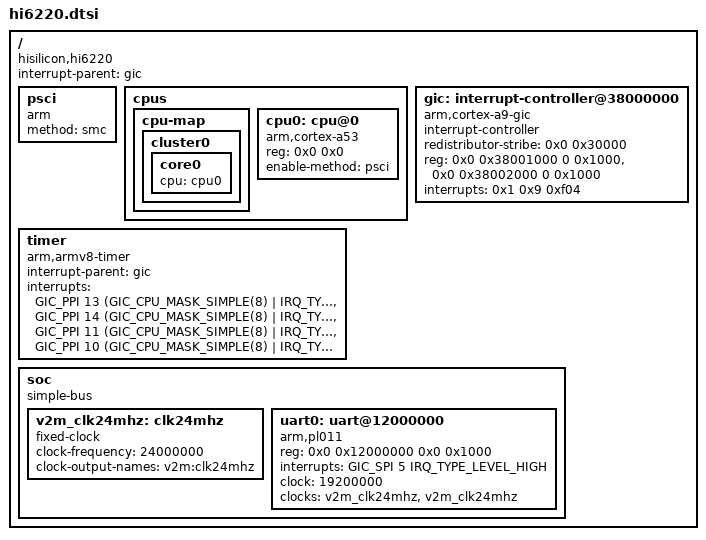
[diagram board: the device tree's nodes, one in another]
/*
 * dts file for Hisilicon Hi6220 SoC
 *
 * Copyright (C) 2015, Hisilicon Ltd.
 */

#include <dt-bindings/interrupt-controller/arm-gic.h>
#include <dt-bindings/clock/hi6220-clock.h>

/ {
	compatible = "hisilicon,hi6220";
	interrupt-parent = <&gic>;
	#address-cells = <2>;
	#size-cells = <2>;

	psci {
		compatible = "arm";
		method = "smc";
	};

	cpus {
		#address-cells = <2>;
		#size-cells = <0>;

		cpu-map {
			cluster0 {
				core0 {
					cpu = <&cpu0>;
				};
			};
		};

		cpu0: cpu@0 {
			compatible = "arm,cortex-a53", "arm,armv8";
			device_type = "cpu";
			reg = <0x0 0x0>;
			enable-method = "psci";
		};


	};

	gic: interrupt-controller@38000000 {
		compatible = "arm,cortex-a9-gic";
		#interrupt-cells = <0x3>;
		#address-cells = <0x2>;
		#size-cells = <0x2>;
		interrupt-controller;
		redistributor-stribe = <0x0 0x30000>;
		reg = <0x0 0x38001000 0 0x1000>, /* GICD */
		      <0x0 0x38002000 0 0x1000>; /* GICC */
		interrupts = <0x1 0x9 0xf04>;
		linux,phandle = <0x1>;
		phandle = <0x1>;
	};

	timer {
		compatible = "arm,armv8-timer";
		interrupt-parent = <&gic>;
		interrupts = <GIC_PPI 13 (GIC_CPU_MASK_SIMPLE(8) | IRQ_TYPE_LEVEL_LOW)>,
			     <GIC_PPI 14 (GIC_CPU_MASK_SIMPLE(8) | IRQ_TYPE_LEVEL_LOW)>,
			     <GIC_PPI 11 (GIC_CPU_MASK_SIMPLE(8) | IRQ_TYPE_LEVEL_LOW)>,
			     <GIC_PPI 10 (GIC_CPU_MASK_SIMPLE(8) | IRQ_TYPE_LEVEL_LOW)>;
	};

	soc {
		compatible = "simple-bus";
		#address-cells = <2>;
		#size-cells = <2>;
		ranges;
/*
		ao_ctrl: ao_ctrl@f7800000 {
			compatible = "hisilicon,hi6220-aoctrl", "syscon";
			reg = <0x0 0xf7800000 0x0 0x2000>;
			#clock-cells = <1>;
		};

		sys_ctrl: sys_ctrl@f7030000 {
			compatible = "hisilicon,hi6220-sysctrl", "syscon";
			reg = <0x0 0xf7030000 0x0 0x2000>;
			#clock-cells = <1>;
			#reset-cells = <1>;
		};

		media_ctrl: media_ctrl@f4410000 {
			compatible = "hisilicon,hi6220-mediactrl", "syscon";
			reg = <0x0 0xf4410000 0x0 0x1000>;
			#clock-cells = <1>;
		}

		pm_ctrl: pm_ctrl@f7032000 {
			compatible = "hisilicon,hi6220-pmctrl", "syscon";
			reg = <0x0 0xf7032000 0x0 0x1000>;
			#clock-cells = <1>;
		};
*/
		v2m_clk24mhz:clk24mhz {
			compatible = "fixed-clock";
			#clock-cells = <0>;
			clock-frequency = <24000000>;
			clock-output-names = "v2m:clk24mhz";
		};

		uart0: uart@12000000 {	/* console */
			compatible = "arm,pl011", "arm,primecell";
			reg = <0x0 0x12000000 0x0 0x1000>;
			interrupts = <GIC_SPI 5 IRQ_TYPE_LEVEL_HIGH>;
			clock = <19200000>;
			clocks = <&v2m_clk24mhz &v2m_clk24mhz>;
			clock-names = "uartclk", "apb_pclk";
		};


	};
};
